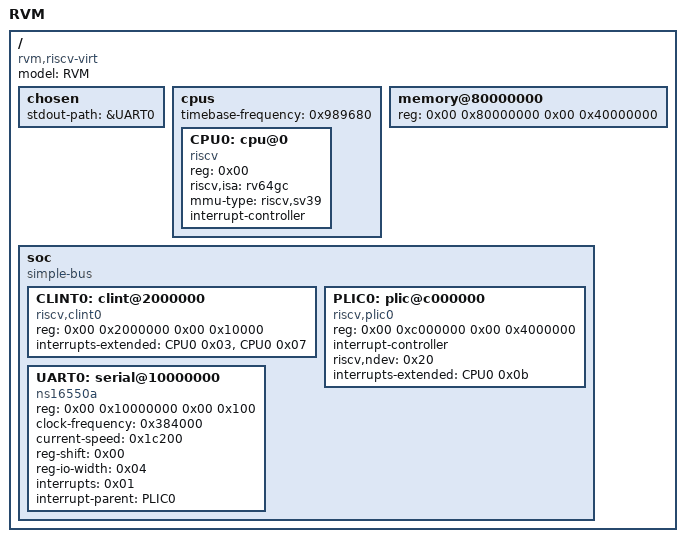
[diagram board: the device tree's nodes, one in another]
/dts-v1/;

/ {
    #address-cells = <0x02>;
    #size-cells = <0x02>;
    compatible = "rvm,riscv-virt";
    model = "RVM";

    chosen {
        stdout-path = &UART0;
    };

    cpus {
        #address-cells = <0x01>;
        #size-cells = <0x00>;
        timebase-frequency = <0x989680>;

        CPU0: cpu@0 {
            device_type = "cpu";
            reg = <0x00>;
            status = "okay";
            compatible = "riscv";
            riscv,isa = "rv64gc";
            mmu-type = "riscv,sv39";
            #interrupt-cells = <0x01>;
            interrupt-controller;
        };
    };

    memory@80000000 {
        device_type = "memory";
        reg = <0x00 0x80000000 0x00 0x40000000>;
    };

    soc {
        #address-cells = <0x02>;
        #size-cells = <0x02>;
        compatible = "simple-bus";
        ranges;

        CLINT0: clint@2000000 {
            compatible = "riscv,clint0";
            reg = <0x00 0x2000000 0x00 0x10000>;
            interrupts-extended = <&CPU0 0x03 &CPU0 0x07>;
        };

        PLIC0: plic@c000000 {
            compatible = "riscv,plic0";
            reg = <0x00 0xc000000 0x00 0x4000000>;
            interrupt-controller;
            #interrupt-cells = <0x01>;
            riscv,ndev = <0x20>;
            interrupts-extended = <&CPU0 0x0b>;
        };

        UART0: serial@10000000 {
            compatible = "ns16550a";
            reg = <0x00 0x10000000 0x00 0x100>;
            clock-frequency = <0x384000>;
            current-speed = <0x1c200>;
            reg-shift = <0x00>;
            reg-io-width = <0x04>;
            interrupts = <0x01>;
            interrupt-parent = <&PLIC0>;
        };
    };
};
